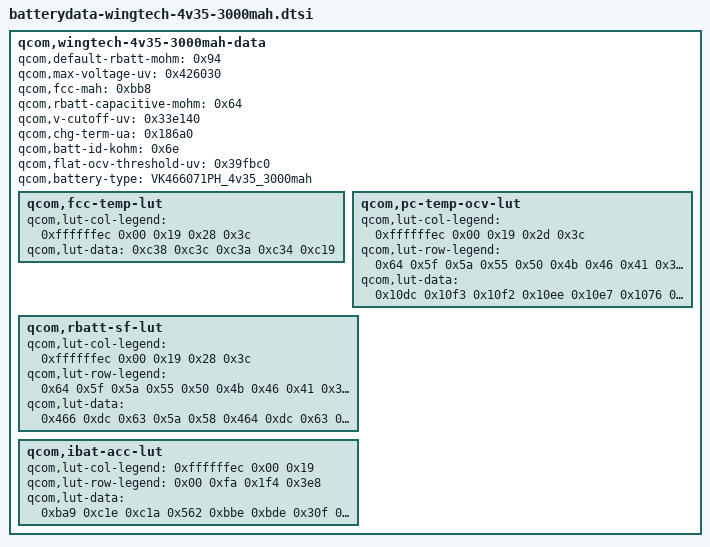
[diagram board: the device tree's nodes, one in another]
/* Copyright (c) 2016, The Linux Foundation. All rights reserved.
 *
 * This program is free software; you can redistribute it and/or modify
 * it under the terms of the GNU General Public License version 2 and
 * only version 2 as published by the Free Software Foundation.
 *
 * This program is distributed in the hope that it will be useful,
 * but WITHOUT ANY WARRANTY; without even the implied warranty of
 * MERCHANTABILITY or FITNESS FOR A PARTICULAR PURPOSE.  See the
 * GNU General Public License for more details.
 */

qcom,wingtech-4v35-3000mah-data {
	qcom,default-rbatt-mohm = <0x94>;
	qcom,max-voltage-uv = <0x426030>;
	qcom,fcc-mah = <0xbb8>;
	qcom,rbatt-capacitive-mohm = <0x64>;
	qcom,v-cutoff-uv = <0x33e140>;
	qcom,chg-term-ua = <0x186a0>;
	qcom,batt-id-kohm = <0x6e>;
	qcom,flat-ocv-threshold-uv = <0x39fbc0>;
	qcom,battery-type = "VK466071PH_4v35_3000mah";

	qcom,fcc-temp-lut {
		qcom,lut-col-legend = <0xffffffec 0x00 0x19 0x28 0x3c>;
		qcom,lut-data = <0xc38 0xc3c 0xc3a 0xc34 0xc19>;
	};

	qcom,pc-temp-ocv-lut {
		qcom,lut-col-legend = <0xffffffec 0x00 0x19 0x2d 0x3c>;
		qcom,lut-row-legend = <0x64 0x5f 0x5a 0x55 0x50 0x4b 0x46 0x41 0x3c 0x37 0x32 0x2d 0x28 0x23 0x1e 0x19 0x14 0x10 0x0d 0x0b 0x0a 0x09 0x08 0x07 0x06 0x05 0x04 0x03 0x02 0x01 0x00>;
		qcom,lut-data = <0x10dc 0x10f3 0x10f2 0x10ee 0x10e7 0x1076 0x10a9 0x10ae 0x10ac 0x10a7 0x1034 0x1070 0x1074 0x1070 0x106e 0xff4 0x103a 0x103c 0x1032 0x1036 0xfb8 0x1008 0x1008 0x1004 0x1001 0xf64 0xfd8 0xfd6 0xfd2 0xfcf 0xf38 0xf8a 0xf9b 0xf9e 0xfa2 0xf14 0xf5e 0xf77 0xf7b 0xf78 0xef2 0xf3c 0xf52 0xf52 0xf50 0xed9 0xf18 0xf23 0xf24 0xf24 0xec8 0xefb 0xf00 0xf00 0xf00 0xeb8 0xee4 0xee8 0xee8 0xee8 0xeaa 0xed2 0xed6 0xed6 0xed4 0xe9b 0xec6 0xec8 0xec7 0xec5 0xe8a 0xebc 0xebb 0xeb7 0xeb1 0xe7c 0xeb0 0xeae 0xea5 0xe98 0xe6f 0xe9e 0xe9d 0xe93 0xe84 0xe56 0xe86 0xe86 0xe7c 0xe6e 0xe4c 0xe77 0xe6e 0xe65 0xe58 0xe3c 0xe71 0xe68 0xe61 0xe55 0xe31 0xe6e 0xe67 0xe60 0xe54 0xe28 0xe6c 0xe66 0xe5e 0xe53 0xe1b 0xe68 0xe65 0xe5d 0xe51 0xe0e 0xe65 0xe62 0xe5a 0xe4e 0xe02 0xe5e 0xe5c 0xe54 0xe48 0xdec 0xe4a 0xe4c 0xe3d 0xe2c 0xdd7 0xe24 0xe22 0xe10 0xe00 0xdba 0xde9 0xde4 0xdd6 0xdc4 0xd79 0xd95 0xd92 0xd82 0xd6f 0xd0a 0xd0c 0xd13 0xd05 0xcee 0xbb8 0xbb8 0xbb8 0xbd0 0xbb8>;
	};

	qcom,rbatt-sf-lut {
		qcom,lut-col-legend = <0xffffffec 0x00 0x19 0x28 0x3c>;
		qcom,lut-row-legend = <0x64 0x5f 0x5a 0x55 0x50 0x4b 0x46 0x41 0x3c 0x37 0x32 0x2d 0x28 0x23 0x1e 0x19 0x14 0x10 0x0d 0x0b 0x0a 0x09 0x08 0x07 0x06 0x05 0x04 0x03 0x02 0x01 0x00>;
		qcom,lut-data = <0x466 0xdc 0x63 0x5a 0x58 0x464 0xdc 0x63 0x5a 0x58 0x434 0xda 0x64 0x5a 0x58 0x3f8 0xdc 0x65 0x59 0x59 0x3cd 0xe0 0x68 0x5c 0x59 0x377 0xe8 0x6c 0x5e 0x5b 0x368 0xd8 0x6d 0x5f 0x5c 0x35d 0xd1 0x73 0x63 0x5f 0x351 0xcc 0x74 0x65 0x61 0x357 0xc3 0x69 0x60 0x5d 0x369 0xc2 0x63 0x5b 0x59 0x37d 0xc3 0x64 0x5b 0x59 0x39a 0xc7 0x65 0x5d 0x5b 0x3bc 0xcb 0x65 0x5f 0x5c 0x3e7 0xd5 0x67 0x5d 0x5c 0x425 0xe0 0x66 0x5b 0x5a 0x470 0xec 0x65 0x5c 0x5b 0x49a 0xf1 0x66 0x5d 0x5b 0x47a 0xee 0x65 0x5b 0x59 0x4ad 0xfb 0x65 0x5c 0x5b 0x4d0 0x103 0x67 0x5d 0x5b 0x4f5 0x10c 0x68 0x5f 0x5d 0x51c 0x11a 0x6a 0x61 0x60 0x545 0x12a 0x6d 0x63 0x63 0x58e 0x138 0x70 0x65 0x63 0x5cf 0x144 0x6f 0x60 0x5d 0x68c 0x14e 0x6b 0x5f 0x5d 0x805 0x16a 0x6f 0x62 0x5f 0xafe 0x1a0 0x78 0x68 0x66 0x15fb 0x340 0xb2 0x97 0x8c 0xcf51 0x6a62 0x6b6e 0x8558 0x3aae>;
	};

	qcom,ibat-acc-lut {
		qcom,lut-col-legend = <0xffffffec 0x00 0x19>;
		qcom,lut-row-legend = <0x00 0xfa 0x1f4 0x3e8>;
		qcom,lut-data = <0xba9 0xc1e 0xc1a 0x562 0xbbe 0xbde 0x30f 0xb43 0xbcc 0x46 0x926 0xba2>;
	};
};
